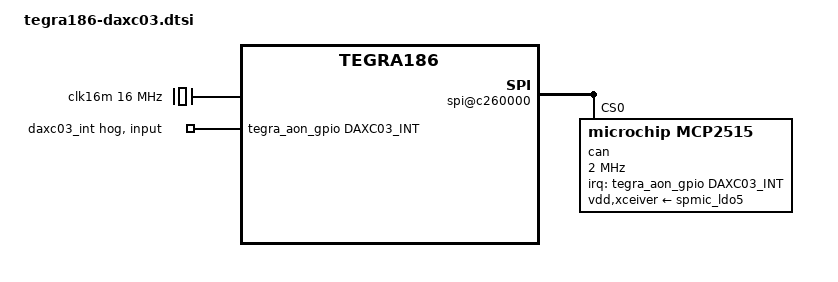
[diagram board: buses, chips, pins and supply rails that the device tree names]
/*
 * This program is free software; you can redistribute it and/or modify
 * it under the terms of the GNU General Public License as published by
 * the Free Software Foundation; either version 2 of the License, or
 * (at your option) any later version.
 *
 * This program is distributed in the hope that it will be useful, but WITHOUT
 * ANY WARRANTY; without even the implied warranty of MERCHANTABILITY or
 * FITNESS FOR A PARTICULAR PURPOSE.  See the GNU General Public License for
 * more details.
 *
 * You should have received a copy of the GNU General Public License
 * along with this program.  If not, see <http://www.gnu.org/licenses/>.
 */

#define DAXC03_INT  TEGRA_AON_GPIO(S, 3)

/ {
	clocks {
		/* 16MHz external crystal oscillator */
		clk16m: mcp251x_osc {
			#clock-cells = <0>;
			compatible = "fixed-clock";
			clock-frequency = <16000000>;
		};
	};

	tegra_aon_gpio: gpio@c2f0000 {
         daxc03_int_b {
            gpio-hog;
            input;
			gpios = <DAXC03_INT 0>;
            label = "daxc03_int";
         };
	};

    /* J23 Expansion Connector SPI0 */
    /* Note the difference in numbering between the connector and device */
    spi@c260000 {
    	status = "okay";
		spi-max-frequency = <2000000>;

		spi-touch-sharp19x12@0 {
			status = "disabled";
		};

		can@0 {
			#address-cells = <0x1>;
			#size-cells = <0x0>;
			compatible = "microchip,mcp2515";
			reg = <0x0>;

			clocks = <&clk16m>;
			interrupt-parent = <&tegra_aon_gpio>;
			interrupts = <DAXC03_INT IRQ_TYPE_EDGE_FALLING>;
			spi-max-frequency = <2000000>;

			vdd-supply = <&spmic_ldo5>;
			xceiver-supply = <&spmic_ldo5>;
		};
    };
};


